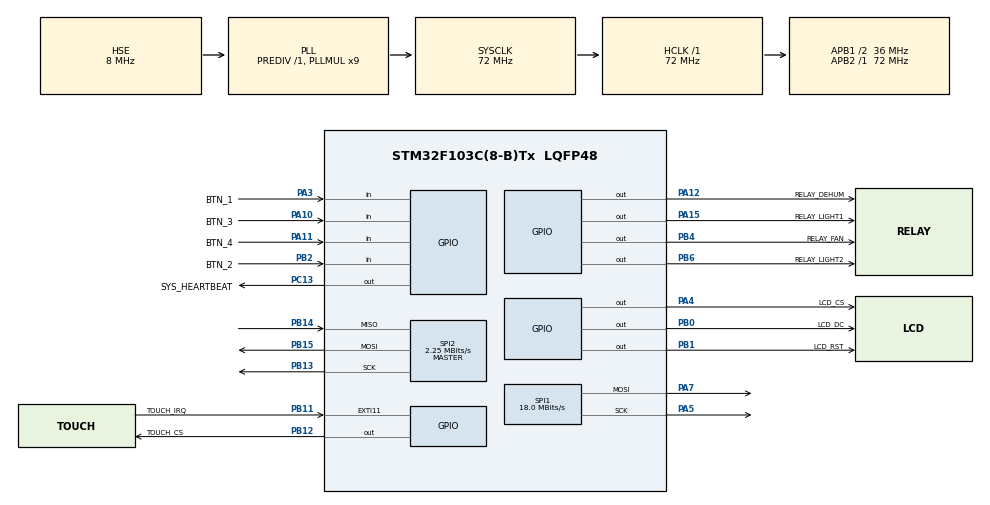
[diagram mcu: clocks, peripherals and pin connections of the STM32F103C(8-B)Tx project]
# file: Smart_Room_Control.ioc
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Mcu.Family=STM32F1
Mcu.Name=STM32F103C(8-B)Tx
Mcu.Package=LQFP48
NVIC.EXTI15_10_IRQn=true\:3\:0\:false\:false\:true\:true\:true\:true
NVIC.PriorityGroup=NVIC_PRIORITYGROUP_4
PA3.GPIO_Label=BTN_1
PA3.GPIO_PuPd=GPIO_PULLUP
PA3.Signal=GPIO_Input
PA4.GPIO_Label=LCD_CS
PA4.GPIO_Speed=GPIO_SPEED_FREQ_HIGH
PA4.Signal=GPIO_Output
PA5.Mode=Full_Duplex_Master
PA5.Signal=SPI1_SCK
PA7.Mode=Full_Duplex_Master
PA7.Signal=SPI1_MOSI
PA10.GPIO_Label=BTN_3
PA10.GPIO_PuPd=GPIO_PULLUP
PA10.Signal=GPIO_Input
PA11.GPIO_Label=BTN_4
PA11.GPIO_PuPd=GPIO_PULLUP
PA11.Signal=GPIO_Input
PA12.GPIO_Label=RELAY_DEHUM
PA12.Signal=GPIO_Output
PA13.Mode=Serial_Wire
PA13.Signal=SYS_JTMS-SWDIO
PA14.Mode=Serial_Wire
PA14.Signal=SYS_JTCK-SWCLK
PA15.GPIO_Label=RELAY_LIGHT1
PA15.Signal=GPIO_Output
PB0.GPIO_Label=LCD_DC
PB0.GPIO_Speed=GPIO_SPEED_FREQ_HIGH
PB0.Signal=GPIO_Output
PB1.GPIO_Label=LCD_RST
PB1.GPIO_Speed=GPIO_SPEED_FREQ_HIGH
PB1.Signal=GPIO_Output
PB2.GPIO_Label=BTN_2
PB2.GPIO_PuPd=GPIO_PULLUP
PB2.Signal=GPIO_Input
PB4.GPIO_Label=RELAY_FAN
PB4.Signal=GPIO_Output
PB6.GPIO_Label=RELAY_LIGHT2
PB6.Signal=GPIO_Output
PB11.GPIO_Label=TOUCH_IRQ
PB11.GPIO_ModeDefaultEXTI=GPIO_MODE_IT_FALLING
PB11.GPIO_PuPd=GPIO_PULLUP
PB11.Signal=GPXTI11
PB12.GPIO_Label=TOUCH_CS
PB12.GPIO_Speed=GPIO_SPEED_FREQ_HIGH
PB12.Signal=GPIO_Output
PB13.Mode=Full_Duplex_Master
PB13.Signal=SPI2_SCK
PB14.Mode=Full_Duplex_Master
PB14.Signal=SPI2_MISO
PB15.Mode=Full_Duplex_Master
PB15.Signal=SPI2_MOSI
PC13-TAMPER-RTC.GPIO_Label=SYS_HEARTBEAT
PC13-TAMPER-RTC.GPIO_ModeDefaultOutputPP=GPIO_MODE_OUTPUT_OD
PC13-TAMPER-RTC.Signal=GPIO_Output
PD0-OSC_IN.Mode=HSE-External-Oscillator
PD0-OSC_IN.Signal=RCC_OSC_IN
PD1-OSC_OUT.Mode=HSE-External-Oscillator
PD1-OSC_OUT.Signal=RCC_OSC_OUT
ProjectManager.HeapSize=0x200
ProjectManager.StackSize=0x400
ProjectManager.TargetToolchain=STM32CubeIDE
RCC.ADCPresc=RCC_ADCPCLK2_DIV6
RCC.AHBFreq_Value=72000000
RCC.APB1CLKDivider=RCC_HCLK_DIV2
RCC.APB1Freq_Value=36000000
RCC.APB1TimFreq_Value=72000000
RCC.APB2Freq_Value=72000000
RCC.APB2TimFreq_Value=72000000
RCC.HCLKFreq_Value=72000000
RCC.PLLMUL=RCC_PLL_MUL9
RCC.PLLSourceVirtual=RCC_PLLSOURCE_HSE
RCC.SYSCLKFreq_VALUE=72000000
RCC.SYSCLKSource=RCC_SYSCLKSOURCE_PLLCLK
RCC.USBFreq_Value=72000000
SPI1.BaudRatePrescaler=SPI_BAUDRATEPRESCALER_4
SPI1.CLKPhase=SPI_PHASE_1EDGE
SPI1.CLKPolarity=SPI_POLARITY_LOW
SPI1.CalculateBaudRate=18.0 MBits/s
SPI1.DataSize=SPI_DATASIZE_8BIT
SPI1.Direction=SPI_DIRECTION_2LINES
SPI1.FirstBit=SPI_FIRSTBIT_MSB
SPI1.Mode=SPI_MODE_MASTER
SPI1.NSS=SPI_NSS_SOFT
SPI1.VirtualType=VM_MASTER
SPI2.BaudRatePrescaler=SPI_BAUDRATEPRESCALER_16
SPI2.CLKPhase=SPI_PHASE_1EDGE
SPI2.CLKPolarity=SPI_POLARITY_LOW
SPI2.CalculateBaudRate=2.25 MBits/s
SPI2.DataSize=SPI_DATASIZE_8BIT
SPI2.Direction=SPI_DIRECTION_2LINES
SPI2.FirstBit=SPI_FIRSTBIT_MSB
SPI2.Mode=SPI_MODE_MASTER
SPI2.NSS=SPI_NSS_SOFT
SPI2.VirtualType=VM_MASTER
SYS.Debug=Serial Wire
board=custom

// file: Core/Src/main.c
/* USER CODE BEGIN Header */
/**
  ******************************************************************************
  * @file           : main.c
  * @brief          : Main program body
  ******************************************************************************
  * @attention
  *
  * Copyright (c) 2026 STMicroelectronics.
  * All rights reserved.
  *
  * This software is licensed under terms that can be found in the LICENSE file
  * in the root directory of this software component.
  * If no LICENSE file comes with this software, it is provided AS-IS.
  *
  ******************************************************************************
  */
/* USER CODE END Header */
#include "main.h"

/* USER CODE BEGIN Includes */
#include "ili9341.h"
#include "xpt2046.h"
#include "button.h"
#include "relay.h"
#include "app.h"
/* USER CODE END Includes */

SPI_HandleTypeDef hspi1;
SPI_HandleTypeDef hspi2;

void SystemClock_Config(void);
static void MX_GPIO_Init(void);
static void MX_SPI1_Init(void);
static void MX_SPI2_Init(void);

int main(void)
{

  /* MCU Configuration--------------------------------------------------------*/

  /* Reset of all peripherals, Initializes the Flash interface and the Systick. */
  HAL_Init();

  /* Configure the system clock */
  SystemClock_Config();

  /* Initialize all configured peripherals */
  MX_GPIO_Init();
  MX_SPI1_Init();
  MX_SPI2_Init();
  /* USER CODE BEGIN 2 */
  /* Initialize Device Drivers */
  ili9341_init();
  xpt2046_init();
  button_init();
  relay_init();

  /* Initialize Application */
  app_init();
  /* USER CODE END 2 */

  /* Infinite loop */
  while (1)
  {

    /* USER CODE BEGIN 3 */
    app_loop();
  }
  /* USER CODE END 3 */
}

void SystemClock_Config(void)
{
  RCC_OscInitTypeDef RCC_OscInitStruct = {0};
  RCC_ClkInitTypeDef RCC_ClkInitStruct = {0};

  /** Initializes the RCC Oscillators according to the specified parameters
  * in the RCC_OscInitTypeDef structure.
  */
  RCC_OscInitStruct.OscillatorType = RCC_OSCILLATORTYPE_HSE;
  RCC_OscInitStruct.HSEState = RCC_HSE_ON;
  RCC_OscInitStruct.HSEPredivValue = RCC_HSE_PREDIV_DIV1;
  RCC_OscInitStruct.HSIState = RCC_HSI_ON;
  RCC_OscInitStruct.PLL.PLLState = RCC_PLL_ON;
  RCC_OscInitStruct.PLL.PLLSource = RCC_PLLSOURCE_HSE;
  RCC_OscInitStruct.PLL.PLLMUL = RCC_PLL_MUL9;
  if (HAL_RCC_OscConfig(&RCC_OscInitStruct) != HAL_OK)
  {
    Error_Handler();
  }

  /** Initializes the CPU, AHB and APB buses clocks
  */
  RCC_ClkInitStruct.ClockType = RCC_CLOCKTYPE_HCLK|RCC_CLOCKTYPE_SYSCLK
                              |RCC_CLOCKTYPE_PCLK1|RCC_CLOCKTYPE_PCLK2;
  RCC_ClkInitStruct.SYSCLKSource = RCC_SYSCLKSOURCE_PLLCLK;
  RCC_ClkInitStruct.AHBCLKDivider = RCC_SYSCLK_DIV1;
  RCC_ClkInitStruct.APB1CLKDivider = RCC_HCLK_DIV2;
  RCC_ClkInitStruct.APB2CLKDivider = RCC_HCLK_DIV1;

  if (HAL_RCC_ClockConfig(&RCC_ClkInitStruct, FLASH_LATENCY_2) != HAL_OK)
  {
    Error_Handler();
  }
}

static void MX_SPI1_Init(void)
{

  /* SPI1 parameter configuration*/
  hspi1.Instance = SPI1;
  hspi1.Init.Mode = SPI_MODE_MASTER;
  hspi1.Init.Direction = SPI_DIRECTION_2LINES;
  hspi1.Init.DataSize = SPI_DATASIZE_8BIT;
  hspi1.Init.CLKPolarity = SPI_POLARITY_LOW;
  hspi1.Init.CLKPhase = SPI_PHASE_1EDGE;
  hspi1.Init.NSS = SPI_NSS_SOFT;
  hspi1.Init.BaudRatePrescaler = SPI_BAUDRATEPRESCALER_4;
  hspi1.Init.FirstBit = SPI_FIRSTBIT_MSB;
  hspi1.Init.TIMode = SPI_TIMODE_DISABLE;
  hspi1.Init.CRCCalculation = SPI_CRCCALCULATION_DISABLE;
  hspi1.Init.CRCPolynomial = 10;
  if (HAL_SPI_Init(&hspi1) != HAL_OK)
  {
    Error_Handler();
  }

}

static void MX_SPI2_Init(void)
{

  /* SPI2 parameter configuration*/
  hspi2.Instance = SPI2;
  hspi2.Init.Mode = SPI_MODE_MASTER;
  hspi2.Init.Direction = SPI_DIRECTION_2LINES;
  hspi2.Init.DataSize = SPI_DATASIZE_8BIT;
  hspi2.Init.CLKPolarity = SPI_POLARITY_LOW;
  hspi2.Init.CLKPhase = SPI_PHASE_1EDGE;
  hspi2.Init.NSS = SPI_NSS_SOFT;
  hspi2.Init.BaudRatePrescaler = SPI_BAUDRATEPRESCALER_16;
  hspi2.Init.FirstBit = SPI_FIRSTBIT_MSB;
  hspi2.Init.TIMode = SPI_TIMODE_DISABLE;
  hspi2.Init.CRCCalculation = SPI_CRCCALCULATION_DISABLE;
  hspi2.Init.CRCPolynomial = 10;
  if (HAL_SPI_Init(&hspi2) != HAL_OK)
  {
    Error_Handler();
  }

}

static void MX_GPIO_Init(void)
{
  GPIO_InitTypeDef GPIO_InitStruct = {0};

  /* GPIO Ports Clock Enable */
  __HAL_RCC_GPIOC_CLK_ENABLE();
  __HAL_RCC_GPIOD_CLK_ENABLE();
  __HAL_RCC_GPIOA_CLK_ENABLE();
  __HAL_RCC_GPIOB_CLK_ENABLE();

  /* Enable AFIO clock and disable JTAG (keep SWD) to free PA15, PB3, PB4 */
  __HAL_RCC_AFIO_CLK_ENABLE();
  __HAL_AFIO_REMAP_SWJ_NOJTAG();

  /* Configure GPIO pin Output Level */
  HAL_GPIO_WritePin(SYS_HEARTBEAT_GPIO_Port, SYS_HEARTBEAT_Pin, GPIO_PIN_RESET);
  HAL_GPIO_WritePin(LCD_CS_GPIO_Port, LCD_CS_Pin, GPIO_PIN_SET);
  HAL_GPIO_WritePin(GPIOB, LCD_DC_Pin|LCD_RST_Pin|TOUCH_CS_Pin, GPIO_PIN_SET);
  HAL_GPIO_WritePin(GPIOA, RELAY_DEHUM_Pin|RELAY_LIGHT1_Pin, GPIO_PIN_RESET);
  HAL_GPIO_WritePin(GPIOB, RELAY_FAN_Pin|RELAY_LIGHT2_Pin, GPIO_PIN_RESET);

  /* Configure GPIO pin : SYS_HEARTBEAT_Pin (PC13) */
  GPIO_InitStruct.Pin = SYS_HEARTBEAT_Pin;
  GPIO_InitStruct.Mode = GPIO_MODE_OUTPUT_OD;
  GPIO_InitStruct.Pull = GPIO_NOPULL;
  GPIO_InitStruct.Speed = GPIO_SPEED_FREQ_LOW;
  HAL_GPIO_Init(SYS_HEARTBEAT_GPIO_Port, &GPIO_InitStruct);

  /* Configure GPIO pin : LCD_CS_Pin (PA4) */
  GPIO_InitStruct.Pin = LCD_CS_Pin;
  GPIO_InitStruct.Mode = GPIO_MODE_OUTPUT_PP;
  GPIO_InitStruct.Pull = GPIO_NOPULL;
  GPIO_InitStruct.Speed = GPIO_SPEED_FREQ_HIGH;
  HAL_GPIO_Init(LCD_CS_GPIO_Port, &GPIO_InitStruct);

  /* Configure GPIO pins : RELAY_DEHUM_Pin (PA12), RELAY_LIGHT1_Pin (PA15) */
  GPIO_InitStruct.Pin = RELAY_DEHUM_Pin|RELAY_LIGHT1_Pin;
  GPIO_InitStruct.Mode = GPIO_MODE_OUTPUT_PP;
  GPIO_InitStruct.Pull = GPIO_NOPULL;
  GPIO_InitStruct.Speed = GPIO_SPEED_FREQ_LOW;
  HAL_GPIO_Init(GPIOA, &GPIO_InitStruct);

  /* Configure GPIO pins : LCD_DC_Pin (PB0), LCD_RST_Pin (PB1), TOUCH_CS_Pin (PB12) */
  GPIO_InitStruct.Pin = LCD_DC_Pin|LCD_RST_Pin|TOUCH_CS_Pin;
  GPIO_InitStruct.Mode = GPIO_MODE_OUTPUT_PP;
  GPIO_InitStruct.Pull = GPIO_NOPULL;
  GPIO_InitStruct.Speed = GPIO_SPEED_FREQ_HIGH;
  HAL_GPIO_Init(GPIOB, &GPIO_InitStruct);

  /* Configure GPIO pins : RELAY_FAN_Pin (PB4), RELAY_LIGHT2_Pin (PB6) */
  GPIO_InitStruct.Pin = RELAY_FAN_Pin|RELAY_LIGHT2_Pin;
  GPIO_InitStruct.Mode = GPIO_MODE_OUTPUT_PP;
  GPIO_InitStruct.Pull = GPIO_NOPULL;
  GPIO_InitStruct.Speed = GPIO_SPEED_FREQ_LOW;
  HAL_GPIO_Init(GPIOB, &GPIO_InitStruct);

  /* Configure GPIO pin : TOUCH_IRQ_Pin (PB11) */
  GPIO_InitStruct.Pin = TOUCH_IRQ_Pin;
  GPIO_InitStruct.Mode = GPIO_MODE_INPUT;
  GPIO_InitStruct.Pull = GPIO_PULLUP;
  HAL_GPIO_Init(TOUCH_IRQ_GPIO_Port, &GPIO_InitStruct);

  /* Configure GPIO pins : BTN_1_Pin (PA3), BTN_3_Pin (PA10), BTN_4_Pin (PA11) */
  GPIO_InitStruct.Pin = BTN_1_Pin|BTN_3_Pin|BTN_4_Pin;
  GPIO_InitStruct.Mode = GPIO_MODE_INPUT;
  GPIO_InitStruct.Pull = GPIO_PULLUP;
  HAL_GPIO_Init(GPIOA, &GPIO_InitStruct);

  /* Configure GPIO pin : BTN_2_Pin (PB2) */
  GPIO_InitStruct.Pin = BTN_2_Pin;
  GPIO_InitStruct.Mode = GPIO_MODE_INPUT;
  GPIO_InitStruct.Pull = GPIO_PULLUP;
  HAL_GPIO_Init(GPIOB, &GPIO_InitStruct);

  /* EXTI interrupt init for TOUCH_IRQ (PB11) */
  HAL_NVIC_SetPriority(EXTI15_10_IRQn, 3, 0);
  HAL_NVIC_EnableIRQ(EXTI15_10_IRQn);
}

/* USER CODE BEGIN 4 */
void HAL_GPIO_EXTI_Callback(uint16_t GPIO_Pin)
{
  (void)GPIO_Pin;
}
/* USER CODE END 4 */

void Error_Handler(void)
{
  __disable_irq();
  while (1)
  {
  }
}
